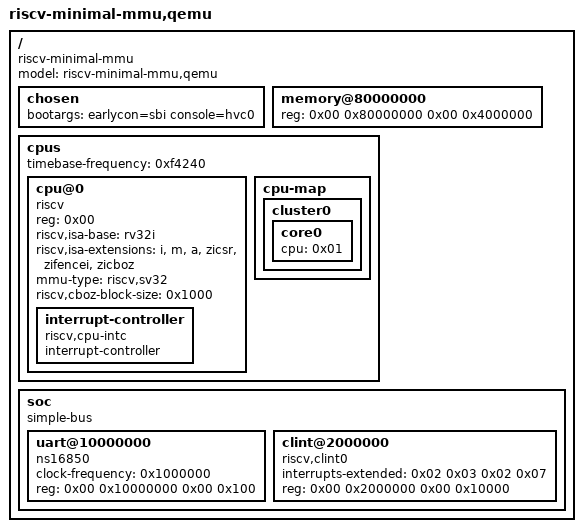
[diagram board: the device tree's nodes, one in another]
/dts-v1/;

/ {
	#address-cells = <0x02>;
	#size-cells = <0x02>;
	compatible = "riscv-minimal-mmu";
	model = "riscv-minimal-mmu,qemu";

	chosen {
		bootargs = "earlycon=sbi console=hvc0";
    };


	memory@80000000 {
		device_type = "memory";
		reg = <0x00 0x80000000 0x00 0x4000000>;
	};

	cpus {
		#address-cells = <0x01>;
		#size-cells = <0x00>;
		timebase-frequency = <0xf4240>;

		cpu@0 {
			phandle = <0x01>;
			device_type = "cpu";
			reg = <0x00>;
			status = "okay";
			compatible = "riscv";
			riscv,isa-base = "rv32i";
			riscv,isa-extensions = "i", "m", "a", "zicsr", "zifencei", "zicboz";
			mmu-type = "riscv,sv32";
			riscv,cboz-block-size = <0x1000>;

			interrupt-controller {
				#interrupt-cells = <0x01>;
				interrupt-controller;
				compatible = "riscv,cpu-intc";
				phandle = <0x02>;
			};
		};

		cpu-map {

			cluster0 {

				core0 {
					cpu = <0x01>;
				};
			};
		};
	};

	soc {
		#address-cells = <0x02>;
		#size-cells = <0x02>;
		compatible = "simple-bus";
		ranges;

		uart@10000000 {
			clock-frequency = <0x1000000>;
			reg = <0x00 0x10000000 0x00 0x100>;
			compatible = "ns16850";
		};

		clint@2000000 {
			interrupts-extended = <0x02 0x03 0x02 0x07>;
			reg = <0x00 0x2000000 0x00 0x10000>;
			compatible = "riscv,clint0";
		};

	};
};
